AUTOSAR XML (schema 4-0-3)
standard types defined: Boolean, UInt32
package /AUTOSAR_Platform/DataConstrs
  range DC_Boolean: raw 0..1
package /PATAC/MSM/ComponentTypes
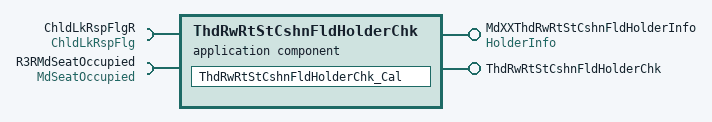
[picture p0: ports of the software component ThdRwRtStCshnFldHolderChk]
  application sw component type ThdRwRtStCshnFldHolderChk
    provide port MdXXThdRwRtStCshnFldHolderInfo: nonqueued-sender-com-spec{data-element=HolderInfo/Val, init-value=0}, provided-interface=HolderInfo
    provide port ThdRwRtStCshnFldHolderChk: server-com-spec{operation=Cal, queue-length=1}, provided-interface=ThdRwRtStCshnFldHolderChk
    require port ChldLkRspFlgR: nonqueued-receiver-com-spec{data-element=ChldLkRspFlg/Val, filter=data-filter-type=ALWAYS, init-value=0}, required-interface=ChldLkRspFlg
    require port R3RMdSeatOccupied: nonqueued-receiver-com-spec{data-element=MdSeatOccupied/Val, filter=data-filter-type=ALWAYS, init-value=0}, required-interface=MdSeatOccupied
    behavior ThdRwRtStCshnFldHolderChk_InternalBehavior
      operation invoked event OIT_ThdRwRtStCshnFldHolderChk_Cal_ThdRwRtStCshnFldHolderChk_Cal: start-on-event=ThdRwRtStCshnFldHolderChk_Cal, operation=ThdRwRtStCshnFldHolderChk.Cal
      runnable ThdRwRtStCshnFldHolderChk_Cal
        data-receive-point-by-arguments:
          access REC_ChldLkRspFlgR_Val: accessed-variable=ChldLkRspFlgR.Val
          access REC_R3RMdSeatOccupied_Val: accessed-variable=R3RMdSeatOccupied.Val
        data-send-points:
          access SEND_MdXXThdRwRtStCshnFldHolderInfo_Val: accessed-variable=MdXXThdRwRtStCshnFldHolderInfo.Val
  swc implementation ThdRwRtStCshnFldHolderChk_Implementation: behavior=ThdRwRtStCshnFldHolderChk_InternalBehavior
    code-descriptors:
      code Default: artifact-descriptors=autosar-engineering-object={short-label=Default, category=SWSRC}
package /PATAC/MSM/ModeAdjust/PortInterface
  client server interface ThdRwRtStCshnFldHolderChk
    operation Cal
  sender receiver interface ChldLkRspFlg: invalidation-policy{data-element=ChldLkRspFlg/Val, handle-invalid=DONT-INVALIDATE}
    data Val: type=Boolean
  sender receiver interface HolderInfo: invalidation-policy{data-element=HolderInfo/Val, handle-invalid=DONT-INVALIDATE}
    data Val: type=UInt32
  sender receiver interface MdSeatOccupied: invalidation-policy{data-element=MdSeatOccupied/Val, handle-invalid=DONT-INVALIDATE}
    data Val: type=Boolean
